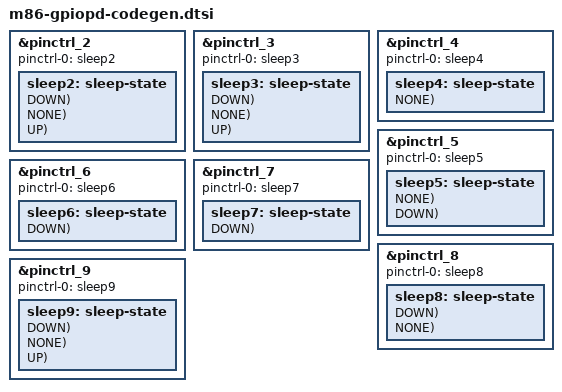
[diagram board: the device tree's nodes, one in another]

#define PIN_CON_INPUT		0
#define PIN_CON_OUTPUT		1

#define PIN_PULL_NONE		0
#define PIN_PULL_DOWN		1
#define PIN_PULL_UP		3

#define PIN_PDN_OUT0		0
#define PIN_PDN_OUT1		1
#define PIN_PDN_INPUT		2
#define PIN_PDN_PREV		3

#define PIN_IN(_pin, _pull)			\
	_pin {						\
		samsung,pins = #_pin;			\
		samsung,pin-function = <0>;		\
		samsung,pin-pud = <PIN_PULL_ ##_pull>;	\
	}

#define PIN_OUT(_pin)				\
	_pin {						\
		samsung,pins = #_pin;			\
		samsung,pin-function = <1>;		\
		samsung,pin-pud = <0>;			\
	}

#define PIN_OUT_SET(_pin, _val)			\
	_pin {						\
		samsung,pins = #_pin;			\
		samsung,pin-function = <1>;		\
		samsung,pin-pud = <0>;			\
		samsung,pin-val	= <_val>;		\
	}

#define PIN_SLP(_pin, _mode, _pull)				\
	_pin {							\
		samsung,pins = #_pin;				\
		samsung,pin-con-pdn = <PIN_PDN_ ##_mode>;	\
		samsung,pin-pud-pdn = <PIN_PULL_ ##_pull>;	\
	}

&pinctrl_2 {
	pinctrl-names = "sleep";
	pinctrl-0 = <&sleep2>;

	sleep2: sleep-state {

		PIN_SLP(gpb0-0, INPUT, DOWN); /* SDA_IR */
		PIN_SLP(gpb0-1, INPUT, DOWN); /* SCL_IR */

		PIN_SLP(gpb0-2, INPUT, DOWN); /* SDA_CHG */
		PIN_SLP(gpb0-3, INPUT, DOWN); /* SCL_CHG */
		PIN_SLP(gpb0-4, INPUT, DOWN); /* BUCK6EN */

		PIN_SLP(gpc0-0, OUT0, DOWN); /* FLASH_STROBE */
		PIN_SLP(gpc0-1, INPUT, DOWN); /* DSI_TE */
		PIN_SLP(gpc0-2, INPUT, DOWN); /* PDA_ACTIVE */
		PIN_SLP(gpc0-3, INPUT, DOWN); /* FLASH_TORCH */
		PIN_SLP(gpc0-4, PREV, NONE); /* FLASH_HWEN   --300Khom pull down register inside LM3644 */
		PIN_SLP(gpc0-5, INPUT, DOWN); /* BCAMPWR_EN   --1Mohm pulldown resistor inside LP5907UVX */
		PIN_SLP(gpc0-6, INPUT, DOWN); /* FCAMPWR_EN   --1Mohm pulldown resistor inside LP5907UVX */
		PIN_SLP(gpc0-7, OUT0, NONE); /* FCAM_RESET */

		PIN_SLP(gpc1-0, INPUT, DOWN); /* AP2CP_DUMP_NOTI_N */
		PIN_SLP(gpc1-1, OUT0, NONE); /* BCAM_RESET */

		PIN_SLP(gpc2-0, INPUT, NONE); /* BCAM_SDA */
		PIN_SLP(gpc2-1, INPUT, NONE); /* BCAM_SCL */
		PIN_SLP(gpc2-2, INPUT, NONE); /* FCAM_SDA */
		PIN_SLP(gpc2-3, INPUT, NONE); /* FCAM_SCL */
		PIN_SLP(gpc2-4, INPUT, NONE); /* FLASH_SDA */
		PIN_SLP(gpc2-5, INPUT, NONE); /* FLASH_SCL */

		PIN_SLP(gpc3-0, PREV, NONE); /* NFC_RESET  */
		PIN_SLP(gpc3-1, OUT0, NONE); /* VCM_EN */
		PIN_SLP(gpc3-2, INPUT, DOWN); /* TSP_RST */
		PIN_SLP(gpc3-3, OUT0, NONE); /* OLED_RESET */
		PIN_SLP(gpc3-4, PREV, DOWN); /* NFC_DL_REQ */
		PIN_SLP(gpc3-5, OUT0, NONE); /* FCAMPWR_EN1 */
		PIN_SLP(gpc3-6, INPUT, NONE); /* PS_INT */
		PIN_SLP(gpc3-7, PREV, NONE); /* NFC_RST_N */

		PIN_SLP(gpd0-0, INPUT, DOWN); /* NC */
		PIN_SLP(gpd0-1, PREV, NONE);  /* WM8998 CODECRESET */
		PIN_SLP(gpd0-2, INPUT, NONE); /* MOTOR_SDA */
		PIN_SLP(gpd0-3, INPUT, NONE); /* MOTOR_SCL */

		PIN_SLP(gpd1-0, INPUT, DOWN); /* GPSRXD */
		PIN_SLP(gpd1-1, INPUT, DOWN); /* GPSTXD */
		PIN_SLP(gpd1-2, INPUT, DOWN); /* GPSCTS */
		PIN_SLP(gpd1-3, INPUT, DOWN); /* GPSRTS */
		PIN_SLP(gpd1-4, INPUT, DOWN); /* AP_RXD */
		PIN_SLP(gpd1-5, INPUT, DOWN); /* AP_TXD */

		PIN_SLP(gpd2-0, INPUT, NONE); /* SDA_MCU */
		PIN_SLP(gpd2-1, INPUT, NONE); /* SCL_MCU */
		PIN_SLP(gpd2-2, INPUT, NONE); /* SDA_NC_CODEC */
		PIN_SLP(gpd2-3, INPUT, NONE); /* SCL_NC_CODEC */
		PIN_SLP(gpd2-4, INPUT, DOWN); /* PWMMOTOR */
		PIN_SLP(gpd2-5, INPUT, DOWN); /* ERR_FG */
		PIN_SLP(gpd2-6, INPUT, NONE); /* SDA_CHG1 */
		PIN_SLP(gpd2-7, INPUT, NONE); /* SCL_CHG1 */

		PIN_SLP(gpd4-0, INPUT, DOWN); /* I2SAP_BCLK */
		PIN_SLP(gpd4-1, INPUT, DOWN); /* NC */
		PIN_SLP(gpd4-2, INPUT, DOWN); /* I2SAP_LRCK */
		PIN_SLP(gpd4-3, INPUT, DOWN); /* I2SAP_DI */
		PIN_SLP(gpd4-4, INPUT, DOWN); /* I2SAP_DO */

		PIN_SLP(gpd5-0, INPUT, NONE); /* ES705 INT_API */
		PIN_SLP(gpd5-1, PREV, NONE);  /* ES705 WKUP_NC */
		PIN_SLP(gpd5-2, INPUT, NONE); /* SDA_MUIC */
		PIN_SLP(gpd5-3, INPUT, NONE); /* SCL_MUIC */

		PIN_SLP(gpd6-0, INPUT, DOWN); /* SPIMISO_NC */
		PIN_SLP(gpd6-1, INPUT, DOWN); /* SPIMOSI_NC */
		PIN_SLP(gpd6-2, OUT0, DOWN); /* SPICLK_NFC */
		PIN_SLP(gpd6-3, OUT0, DOWN); /* SPICS_NFC */
		PIN_SLP(gpd6-4, INPUT, DOWN); /* SPIMISO_NFC */
		PIN_SLP(gpd6-5, INPUT, DOWN); /* SPIMOSI_NFC */

		PIN_SLP(gpd7-0, INPUT, DOWN); /* BCAM_MCLK */
		PIN_SLP(gpd7-1, INPUT, DOWN); /* FCAM_MCLK */
		PIN_SLP(gpd7-2, OUT0, NONE); /* PS_EN */

		PIN_SLP(gpd8-0, INPUT, DOWN); /* SPICLK_NC */
		PIN_SLP(gpd8-1, INPUT, DOWN); /* SPICS_NC */

		PIN_SLP(gpg0-0, PREV, UP); /*CP_PMIC_PWR_EN */
		PIN_SLP(gpg0-1, INPUT, DOWN); /* DSI_TE */


		PIN_SLP(gpg3-2, INPUT, NONE); /* SDA_TOUCH */
		PIN_SLP(gpg3-3, INPUT, NONE); /* SCL_TOUCH */
		PIN_SLP(gpg3-0, INPUT, NONE); /* SDA_PMIC */
		PIN_SLP(gpg3-1, INPUT, NONE); /* SCL_PMIC */
	};
};

&pinctrl_3 {
	pinctrl-names = "sleep";
	pinctrl-0 = <&sleep3>;

	sleep3: sleep-state {

		PIN_SLP(gpf0-0, INPUT, DOWN);

		PIN_SLP(gpf0-1, INPUT, DOWN); /* NC */
		PIN_SLP(gpf0-2, PREV, NONE); /* NC */ /*there is error :can not wakeup*/
		PIN_SLP(gpf0-3, INPUT, DOWN); /* NC *//*there is error :can not wakeup*/
		PIN_SLP(gpf0-4, INPUT, DOWN); /* DAC_RESET(ES9018) */
		PIN_SLP(gpf0-5, INPUT, DOWN); /* NC */
		PIN_SLP(gpf0-6, INPUT, NONE); /* PCIE_CLKREQ_WIFI */
		PIN_SLP(gpf0-7, INPUT, NONE); /* NC */

		PIN_SLP(gpf1-0, INPUT, DOWN);	/* LOW_GAIN(ES9018) */
		PIN_SLP(gpf1-1, INPUT, DOWN); /* MOTOR_EN */
		PIN_SLP(gpf1-2, PREV, NONE); /* NFC_DL_REQ */
		PIN_SLP(gpf1-3, PREV, NONE);	/* MUTE(ES9018)*/
		PIN_SLP(gpf1-4, PREV, NONE);	/* OUT_SELECT(ES9018)*/
		PIN_SLP(gpf1-5, INPUT, DOWN); /* DL_EN */
		PIN_SLP(gpf1-6, PREV, NONE); /* NFC_RST_N */
		PIN_SLP(gpf1-7, INPUT, DOWN);	/* */

		PIN_SLP(gpf2-0, INPUT, DOWN); /* NC */
		PIN_SLP(gpf2-1, OUT0, NONE); /* MCLK_EN(ES9018) */
		PIN_SLP(gpf2-2, INPUT, DOWN); /* DVDD29_TF SUPPLY */
		PIN_SLP(gpf2-3, OUT0, NONE); /* MCLK_EN1(ES9018) */

		PIN_SLP(gpf3-0, PREV, NONE);  /* NC */
		PIN_SLP(gpf3-1, PREV, NONE);  /* TFA9890 RESETN_PA*/
		PIN_SLP(gpf3-2, INPUT, DOWN); /* NC*/
		PIN_SLP(gpf3-3, INPUT, DOWN); /* WKUP_MCU*/
		PIN_SLP(gpf3-4, INPUT, DOWN); /* NC*/

		PIN_SLP(gpf4-0, PREV, NONE); /* BT_DEV_WAKE */
		PIN_SLP(gpf4-1, INPUT, DOWN); /* DAC_ON(ES9018)*/
		PIN_SLP(gpf4-2, INPUT, DOWN); /* AP2CP_DUMP_NOTI_N */
		PIN_SLP(gpf4-3, INPUT, DOWN); /* NC */
		PIN_SLP(gpf4-4, INPUT, DOWN); /* NC */
		PIN_SLP(gpf4-5, INPUT, DOWN); /* MCU_BUSY */
		PIN_SLP(gpf4-6, PREV, NONE); /* GPSPOWERON */
		PIN_SLP(gpf4-7, INPUT, DOWN);	/* */

		PIN_SLP(gpf5-0, INPUT, DOWN); /* OP_EN(ES9018) */
		PIN_SLP(gpf5-1, INPUT, DOWN); /* NC */
		PIN_SLP(gpf5-2, INPUT, DOWN); /* NC */
		PIN_SLP(gpf5-3, INPUT, DOWN); /* NC */
		PIN_SLP(gpf5-4, PREV, NONE); /* LED_EN*/
		PIN_SLP(gpf5-5, PREV, NONE);  /* ES705 RESET */
		PIN_SLP(gpf5-6, PREV, NONE);  /* wlan_reg_on */
		PIN_SLP(gpf5-7, PREV, NONE);  /* BT_REG_ON */

		PIN_SLP(gpg1-0, INPUT, DOWN); /* SMPL_WARN */
		PIN_SLP(gpg1-1, INPUT, DOWN); /* PMIC_BUCK6_DVS */
		PIN_SLP(gpg1-2, PREV, UP);    /* AP_RST_CP */
		PIN_SLP(gpg1-3, INPUT, NONE); /* BOOST_SDA */
		PIN_SLP(gpg1-4, INPUT, NONE); /* BOOST_SCL */

		PIN_SLP(gpg2-0, PREV, NONE);	/*pcie_reset_wifi*/
		PIN_SLP(gpg2-1, INPUT, DOWN);
		PIN_SLP(gpg2-2, INPUT, DOWN);
		PIN_SLP(gpg2-3, INPUT, DOWN);
		PIN_SLP(gpg2-4, INPUT, DOWN);

		PIN_SLP(gph1-0, INPUT, NONE);
		PIN_SLP(gph1-1, INPUT, DOWN);
		PIN_SLP(gph1-2, INPUT, DOWN);
		PIN_SLP(gph1-3, INPUT, UP);
		PIN_SLP(gph1-4, OUT1, UP);	
		PIN_SLP(gph1-5, INPUT, DOWN);

		PIN_SLP(gpv6-0, INPUT, DOWN);/*error :wakeup*/
		PIN_SLP(gpv6-1, INPUT, NONE);
		PIN_SLP(gpv6-2, PREV, NONE); /* XBOOTLDO1 */

	};

};

&pinctrl_4 {
	pinctrl-names = "sleep";
	pinctrl-0 = <&sleep4>;
	sleep4: sleep-state {
		PIN_SLP(gpj0-0, INPUT, NONE); /* SDA_CHG1*/
		PIN_SLP(gpj0-1, INPUT, NONE); /* SCL_CHG1*/
		PIN_SLP(gpj0-2, PREV, NONE);  /* WM8998 AUEN */
	};
};

&pinctrl_5 {
	pinctrl-names = "sleep";
	pinctrl-0 = <&sleep5>;
	sleep5: sleep-state {
		PIN_SLP(gpj1-0, INPUT, NONE);
		PIN_SLP(gpj1-1, INPUT, NONE);
		PIN_SLP(gpj1-2, INPUT, DOWN);
	};
};

&pinctrl_6 {
	pinctrl-names = "sleep";
	pinctrl-0 = <&sleep6>;
	sleep6: sleep-state {
		PIN_SLP(gpg4-0, INPUT, DOWN);
		PIN_SLP(gpg4-1, INPUT, DOWN);
		PIN_SLP(gpg4-2, INPUT, DOWN);
		PIN_SLP(gpg4-3, INPUT, DOWN);
	};
};

&pinctrl_7 {
	pinctrl-names = "sleep";
	pinctrl-0 = <&sleep7>;
	sleep7: sleep-state {
		PIN_SLP(gpv7-0, INPUT, DOWN);
		PIN_SLP(gpv7-1, INPUT, DOWN);
		PIN_SLP(gpv7-2, INPUT, DOWN);
		PIN_SLP(gpv7-3, INPUT, DOWN);
		PIN_SLP(gpv7-4, INPUT, DOWN);
	};
};

&pinctrl_8 {
	pinctrl-names = "sleep";
	pinctrl-0 = <&sleep8>;
	sleep8: sleep-state {
		PIN_SLP(gpr4-0, INPUT, DOWN);
		PIN_SLP(gpr4-1, INPUT, NONE);
		PIN_SLP(gpr4-2, INPUT, NONE);
		PIN_SLP(gpr4-3, INPUT, NONE);
		PIN_SLP(gpr4-4, INPUT, NONE);	
		PIN_SLP(gpr4-5, INPUT, NONE);
		PIN_SLP(gpr4-6, INPUT, NONE);
	};
};

&pinctrl_9 {
	pinctrl-names = "sleep";
	pinctrl-0 = <&sleep9>;
	sleep9: sleep-state {
		PIN_SLP(gpr0-0, INPUT, DOWN); /* NC */
		PIN_SLP(gpr0-1, INPUT, NONE); /* NC */
		PIN_SLP(gpr0-2, INPUT, DOWN); /* NC */
		PIN_SLP(gpr0-3, INPUT, DOWN); /* NC */

		PIN_SLP(gpr1-0, INPUT, NONE); /* LEDC1 */
		PIN_SLP(gpr1-1, INPUT, NONE); /* LEDC2 */
		PIN_SLP(gpr1-2, INPUT, NONE); /* LEDC3 */
		PIN_SLP(gpr1-3, INPUT, NONE); /* LEDC4 */
		PIN_SLP(gpr1-4, INPUT, NONE); /* LEDC5 */
		PIN_SLP(gpr1-5, INPUT, NONE); /* LEDC6 */
		PIN_SLP(gpr1-6, INPUT, NONE); /* LED_EN */
		PIN_SLP(gpr1-7, INPUT, NONE); /* NC */

		PIN_SLP(gpr2-0, INPUT, DOWN); /* NC */
		PIN_SLP(gpr2-1, INPUT, NONE); /* NC */
		PIN_SLP(gpr2-2, INPUT, DOWN); /* NC */
		PIN_SLP(gpr2-3, INPUT, DOWN); /* NC */
		PIN_SLP(gpr2-4, INPUT, DOWN); /* NC */

		PIN_SLP(gpr3-0, OUT0, DOWN); /* CHG1_EN*/
		PIN_SLP(gpr3-1, PREV, UP); /* AP2CP_STATUS */
		PIN_SLP(gpr3-2, OUT0, DOWN); /* CHG2_EN */
		PIN_SLP(gpr3-3, INPUT, NONE); /* LEDC5 */
		PIN_SLP(gpr3-4, INPUT, DOWN); /* PD_ON*/
		PIN_SLP(gpr3-5, INPUT, NONE); /* LEDC6 */
		PIN_SLP(gpr3-6, INPUT, NONE); /* LEDC3*/
		PIN_SLP(gpr3-7, PREV, UP); /* AP2CP_WAKEUP */
	};
};
